# WS63 register map
File version: 1.0
CPU: other r0p0, little endian, MPU, FPU, 3 interrupt priority bits
Registers are 32-bit, read-write, reset 0x0 unless marked. A register's access mark holds for its fields unless they carry their own. Offsets are from the block's base; [hi:lo] are bit positions.

## CLDO_CRG — CLDO Clock and Reset Generator - clock enables, dividers, clock selects, soft resets
Base 0x44001100
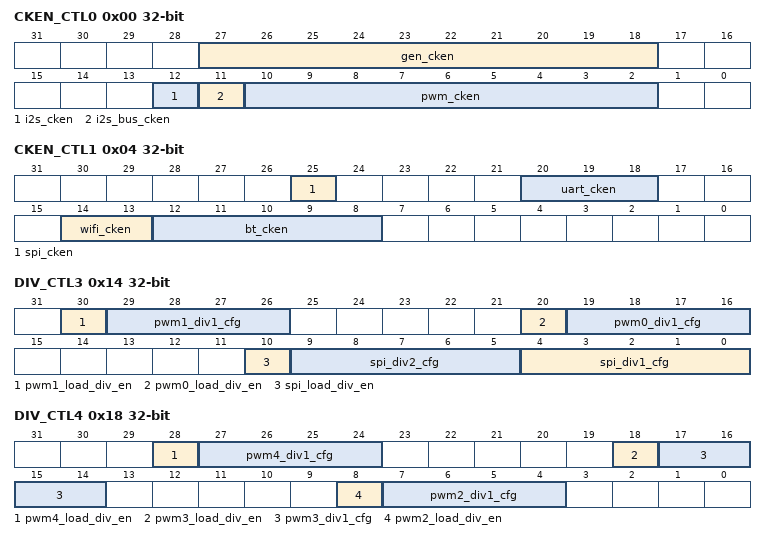
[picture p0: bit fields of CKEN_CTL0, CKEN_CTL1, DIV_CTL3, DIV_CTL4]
0x00 CKEN_CTL0 — Clock enable control register 0
  [27:18] gen_cken — General clock gates: bits [27:18], 10 channels
  [12] i2s_cken — I2S/SIO functional clock gate
  [11] i2s_bus_cken — I2S/SIO bus clock gate
  [10:2] pwm_cken — PWM clock gates: bits [10:2], 9 channels
0x04 CKEN_CTL1 — Clock enable control register 1
  [25] spi_cken — SPI clock gate at bit 25
  [20:18] uart_cken — UART clock gates: bits [20:18], 3 channels
  [14:13] wifi_cken — WIFI clock gates: bits [14:13], 2 channels
  [12:8] bt_cken — BT clock gates: bits [12:8], 5 channels
0x08 DIV_CTL0 — Divider control register 0
  [31:0] div_ctl0 — Clock divider control 0
0x14 DIV_CTL3 — Divider control 3 - PWM0, PWM1
  [30] pwm1_load_div_en — PWM1 divider load enable latch bit
  [29:26] pwm1_div1_cfg — PWM1 divider value
  [20] pwm0_load_div_en — PWM0 divider load enable latch bit
  [19:16] pwm0_div1_cfg — PWM0 divider value
  [10] spi_load_div_en — SPI divider load enable latch bit
  [9:5] spi_div2_cfg — SPI divider stage 2 value written by spi_porting_clock_init
  [4:0] spi_div1_cfg — SPI divider stage 1 value written by spi_porting_clock_init
0x18 DIV_CTL4 — Divider control 4 - PWM2, PWM3, PWM4
  [28] pwm4_load_div_en — PWM4 divider load enable latch bit
  [27:24] pwm4_div1_cfg — PWM4 divider value
  [18] pwm3_load_div_en — PWM3 divider load enable latch bit
  [17:14] pwm3_div1_cfg — PWM3 divider value
  [8] pwm2_load_div_en — PWM2 divider load enable latch bit
  [7:4] pwm2_div1_cfg — PWM2 divider value
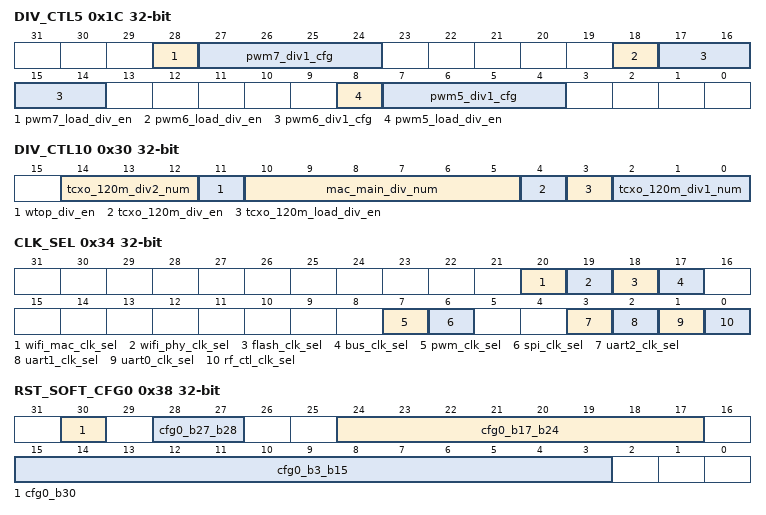
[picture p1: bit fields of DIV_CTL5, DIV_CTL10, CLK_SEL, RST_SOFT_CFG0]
0x1C DIV_CTL5 — Divider control 5 - PWM5, PWM6, PWM7
  [28] pwm7_load_div_en — PWM7 divider load enable latch bit
  [27:24] pwm7_div1_cfg — PWM7 divider value
  [18] pwm6_load_div_en — PWM6 divider load enable latch bit
  [17:14] pwm6_div1_cfg — PWM6 divider value
  [8] pwm5_load_div_en — PWM5 divider load enable latch bit
  [7:4] pwm5_div1_cfg — PWM5 divider value
0x24 DIV_CTL7 — Divider control 7 - tsensor, bus
  [31:0] div_tsensor_bus — TSENSOR and bus clock dividers
0x2C DIV_CTL9 — Divider control 9 - TRNG
  [31:0] div_trng — TRNG clock divider
0x30 DIV_CTL10 — Divider control 10 - TCXO 120M, MAC main
  [14:12] tcxo_120m_div2_num — TCXO 120M divider 2 value (3-bit)
  [11] wtop_div_en — WTO divider enable
  [10:5] mac_main_div_num — MAC main divider value (6-bit)
  [4] tcxo_120m_div_en — TCXO 120M divider enable
  [3] tcxo_120m_load_div_en — TCXO 120M load divider enable
  [2:0] tcxo_120m_div1_num — TCXO 120M divider 1 value (3-bit)
0x34 CLK_SEL — Clock source select register
  [20] wifi_mac_clk_sel — WIFI_MAC clock select
  [19] wifi_phy_clk_sel — WIFI_PHY clock select
  [18] flash_clk_sel — Flash clock: 0=TCXO; 1=PLL
  [17] bus_clk_sel — Bus clock select
  [7] pwm_clk_sel — PWM clock: 0=TCXO; 1=PLL
  [6] spi_clk_sel — SPI clock select
  [3] uart2_clk_sel — UART2 clock select
  [2] uart1_clk_sel — UART1 clock select
  [1] uart0_clk_sel — UART0 clock: 0=TCXO; 1=PLL
  [0] rf_ctl_clk_sel — RF_CTL clock: 0=TCXO; 1=PLL
0x38 RST_SOFT_CFG0 — Soft reset configuration register 0
  [30] cfg0_b30 — Soft reset bit 30
  [28:27] cfg0_b27_b28 — 2-bit soft reset control (bits [28:27])
  [24:17] cfg0_b17_b24 — 8-bit soft reset control (bits [24:17])
  [15:3] cfg0_b3_b15 — 13-bit soft reset control (bits [15:3])
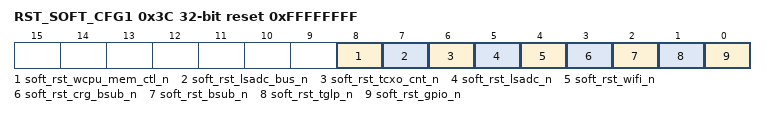
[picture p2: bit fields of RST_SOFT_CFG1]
0x3C RST_SOFT_CFG1 reset 0xFFFFFFFF — Soft reset configuration register 1 (active low)
  [8] soft_rst_wcpu_mem_ctl_n — WCPU memory controller reset: 0=reset; 1=released
  [7] soft_rst_lsadc_bus_n — LSADC bus interface reset: 0=reset; 1=released
  [6] soft_rst_tcxo_cnt_n — TCXO counter reset: 0=reset; 1=released
  [5] soft_rst_lsadc_n — LSADC core reset: 0=reset; 1=released
  [4] soft_rst_wifi_n — WIFI subsystem reset: 0=reset; 1=released
  [3] soft_rst_crg_bsub_n — CRG BSUB (BT) reset: 0=reset; 1=released
  [2] soft_rst_bsub_n — BSUB (BT) reset: 0=reset; 1=released
  [1] soft_rst_tglp_n — TGLP (BT) reset: 0=reset; 1=released
  [0] soft_rst_gpio_n — GPIO module reset: 0=reset; 1=released
0x44 I2S_DIV_CFG — I2S/SIO MCLK divider configuration
  [31:0] i2s_mclk_div_num — I2S MCLK divider number written by sio_porting_set_sample_rate
